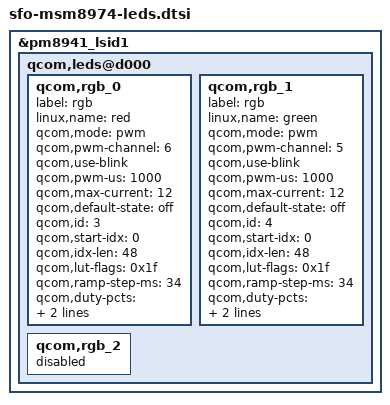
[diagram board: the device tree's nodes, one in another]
/*
 * Copyright (c) 2012-2013, The Linux Foundation. All rights reserved.
 *
 * This program is free software; you can redistribute it and/or modify
 * it under the terms of the GNU General Public License version 2 and
 * only version 2 as published by the Free Software Foundation.
 *
 * This program is distributed in the hope that it will be useful,
 * but WITHOUT ANY WARRANTY; without even the implied warranty of
 * MERCHANTABILITY or FITNESS FOR A PARTICULAR PURPOSE.  See the
 * GNU General Public License for more details.
 */

&pm8941_lsid1 {
	qcom,leds@d000 {
		status = "okay";
		qcom,rgb_0 {
			label = "rgb";
			linux,name = "red";
			qcom,mode = "pwm";
			qcom,pwm-channel = <6>;
			qcom,use-blink;
			qcom,pwm-us = <1000>;
			qcom,max-current = <12>;
			qcom,default-state = "off";
			qcom,id = <3>;
			qcom,start-idx = <0>;
			qcom,idx-len = <48>;
			qcom,lut-flags = <0x1f>;
			qcom,ramp-step-ms = <34>;
			qcom,duty-pcts =
				[00 00 00 00 00 00 00 01 02 03 04 05
				06 08 0a 0c 0d 0f 14 18 1c 1f 24 28
				2c 2f 34 38 3c 3f 45 4a 4f 55 5a 5f
				67 6f 77 7f 8f 9f af bf cf df ef ff];
			linux,default-trigger = "none";
		};

		qcom,rgb_1 {
			label = "rgb";
			linux,name = "green";
			qcom,mode = "pwm";
			qcom,pwm-channel = <5>;
			qcom,use-blink;
			qcom,pwm-us = <1000>;
			qcom,max-current = <12>;
			qcom,default-state = "off";
			qcom,id = <4>;
			qcom,start-idx = <0>;
			qcom,idx-len = <48>;
			qcom,lut-flags = <0x1f>;
			qcom,ramp-step-ms = <34>;
			qcom,duty-pcts =
				[00 00 00 00 00 00 00 01 02 03 04 05
				06 08 0a 0c 0d 0f 14 18 1c 1f 24 28
				2c 2f 34 38 3c 3f 45 4a 4f 55 5a 5f
				67 6f 77 7f 8f 9f af bf cf df ef ff];
			linux,default-trigger = "none";
		};

		qcom,rgb_2 {
			status = "disabled";
		};
	};
};
